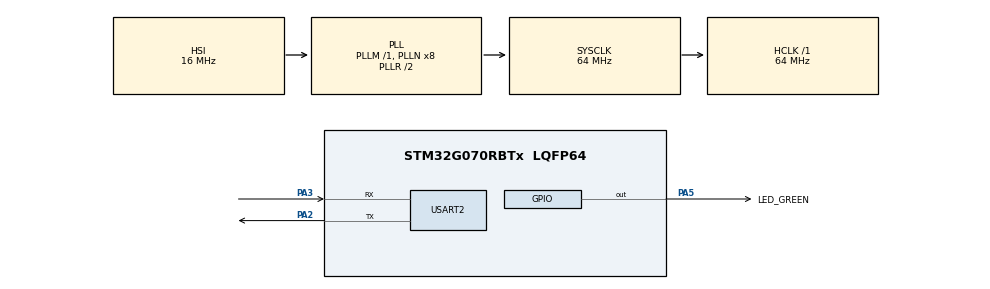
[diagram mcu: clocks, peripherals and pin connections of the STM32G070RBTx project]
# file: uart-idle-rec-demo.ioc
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Dma.Request0=USART2_RX
Dma.Request1=USART2_TX
Dma.USART2_RX.0.Direction=DMA_PERIPH_TO_MEMORY
Dma.USART2_RX.0.EventEnable=DISABLE
Dma.USART2_RX.0.Instance=DMA1_Channel1
Dma.USART2_RX.0.MemDataAlignment=DMA_MDATAALIGN_BYTE
Dma.USART2_RX.0.MemInc=DMA_MINC_ENABLE
Dma.USART2_RX.0.Mode=DMA_CIRCULAR
Dma.USART2_RX.0.PeriphDataAlignment=DMA_PDATAALIGN_BYTE
Dma.USART2_RX.0.PeriphInc=DMA_PINC_DISABLE
Dma.USART2_RX.0.Polarity=HAL_DMAMUX_REQ_GEN_RISING
Dma.USART2_RX.0.Priority=DMA_PRIORITY_LOW
Dma.USART2_RX.0.RequestNumber=1
Dma.USART2_RX.0.SignalID=NONE
Dma.USART2_RX.0.SyncEnable=DISABLE
Dma.USART2_RX.0.SyncPolarity=HAL_DMAMUX_SYNC_NO_EVENT
Dma.USART2_RX.0.SyncRequestNumber=1
Dma.USART2_RX.0.SyncSignalID=NONE
Dma.USART2_TX.1.Direction=DMA_MEMORY_TO_PERIPH
Dma.USART2_TX.1.EventEnable=DISABLE
Dma.USART2_TX.1.Instance=DMA1_Channel2
Dma.USART2_TX.1.MemDataAlignment=DMA_MDATAALIGN_BYTE
Dma.USART2_TX.1.MemInc=DMA_MINC_ENABLE
Dma.USART2_TX.1.Mode=DMA_NORMAL
Dma.USART2_TX.1.PeriphDataAlignment=DMA_PDATAALIGN_BYTE
Dma.USART2_TX.1.PeriphInc=DMA_PINC_DISABLE
Dma.USART2_TX.1.Polarity=HAL_DMAMUX_REQ_GEN_RISING
Dma.USART2_TX.1.Priority=DMA_PRIORITY_LOW
Dma.USART2_TX.1.RequestNumber=1
Dma.USART2_TX.1.SignalID=NONE
Dma.USART2_TX.1.SyncEnable=DISABLE
Dma.USART2_TX.1.SyncPolarity=HAL_DMAMUX_SYNC_NO_EVENT
Dma.USART2_TX.1.SyncRequestNumber=1
Dma.USART2_TX.1.SyncSignalID=NONE
FREERTOS.BinarySemaphores01=uart_tx_lock,Dynamic,NULL
FREERTOS.Queues01=upper_queue,16,uart_buf_t,0,Dynamic,NULL,NULL
FREERTOS.Tasks01=defaultTask,24,128,StartDefaultTask,Default,NULL,Dynamic,NULL,NULL
FREERTOS.configUSE_NEWLIB_REENTRANT=1
Mcu.Family=STM32G0
Mcu.Name=STM32G070RBTx
Mcu.Package=LQFP64
NVIC.DMA1_Channel1_IRQn=true\:3\:0\:false\:false\:true\:true\:false\:true\:true
NVIC.DMA1_Channel2_3_IRQn=true\:3\:0\:false\:false\:true\:true\:false\:true\:true
NVIC.TIM1_BRK_UP_TRG_COM_IRQn=true\:3\:0\:false\:false\:true\:false\:false\:true\:true
NVIC.TimeBase=TIM1_BRK_UP_TRG_COM_IRQn
NVIC.TimeBaseIP=TIM1
NVIC.USART2_IRQn=true\:3\:0\:false\:false\:true\:true\:true\:true\:true
PA13.GPIO_Label=TMS
PA13.Mode=Serial_Wire
PA13.Signal=SYS_SWDIO
PA14-BOOT0.GPIO_Label=TCK
PA14-BOOT0.Mode=Serial_Wire
PA14-BOOT0.Signal=SYS_SWCLK
PA2.GPIO_PuPd=GPIO_PULLUP
PA2.Mode=Asynchronous
PA2.Signal=USART2_TX
PA3.GPIO_PuPd=GPIO_PULLUP
PA3.Mode=Asynchronous
PA3.Signal=USART2_RX
PA5.GPIO_Label=LED_GREEN
PA5.GPIO_Speed=GPIO_SPEED_FREQ_HIGH
PA5.Signal=GPIO_Output
PC13.Mode=SYS_WakeUp1
PC13.Signal=SYS_WKUP2
PC14-OSC32_IN\ (PC14).Mode=LSE-External-Oscillator
PC14-OSC32_IN\ (PC14).Signal=RCC_OSC32_IN
PC15-OSC32_OUT\ (PC15).Mode=LSE-External-Oscillator
PC15-OSC32_OUT\ (PC15).Signal=RCC_OSC32_OUT
PF0-OSC_IN\ (PF0).GPIO_Label=MCO
PF0-OSC_IN\ (PF0).Mode=HSE-External-Clock-Source
PF0-OSC_IN\ (PF0).Signal=RCC_OSC_IN
ProjectManager.HeapSize=0x200
ProjectManager.StackSize=0x400
ProjectManager.TargetToolchain=STM32CubeIDE
RCC.ADCFreq_Value=64000000
RCC.AHBFreq_Value=64000000
RCC.CortexFreq_Value=64000000
RCC.EXTERNAL_CLOCK_VALUE=12288000
RCC.HCLKFreq_Value=64000000
RCC.HSE_VALUE=8000000
RCC.HSI_VALUE=16000000
RCC.SYSCLKFreq_VALUE=64000000
RCC.SYSCLKSource=RCC_SYSCLKSOURCE_PLLCLK
RCC.VCOOutputFreq_Value=128000000
USART2.VirtualMode-Asynchronous=VM_ASYNC
USART2.WordLength=WORDLENGTH_8B
VP_FREERTOS_VS_CMSIS_V2.Mode=CMSIS_V2
VP_SYS_VS_tim1.Mode=TIM1
board=NUCLEO-G070RB

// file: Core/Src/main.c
/* USER CODE BEGIN Header */
/**
  ******************************************************************************
  * @file           : main.c
  * @brief          : Main program body
  ******************************************************************************
  * @attention
  *
  * Copyright (c) 2022 STMicroelectronics.
  * All rights reserved.
  *
  * This software is licensed under terms that can be found in the LICENSE file
  * in the root directory of this software component.
  * If no LICENSE file comes with this software, it is provided AS-IS.
  *
  ******************************************************************************
  */
/* USER CODE END Header */
#include "main.h"
#include "cmsis_os.h"
#include "dma.h"
#include "usart.h"
#include "gpio.h"

/* USER CODE BEGIN Includes */
#include "string.h"
/* USER CODE END Includes */

/* USER CODE BEGIN PV */
uint8_t u2_buf[64];

volatile uint8_t u2_rx_start_pos = 0;
volatile uint8_t u2_rx_length = 0;

extern osMessageQueueId_t upper_queueHandle;
/* USER CODE END PV */

void SystemClock_Config(void);
void MX_FREERTOS_Init(void);

/* USER CODE BEGIN 0 */
void HAL_UART_ErrorCallback(UART_HandleTypeDef *huart) {
	// handle when baudrate set error
	// reset uart
//    static const char *TAG = "UART_ERR";
    uint32_t err;
    if ((err = HAL_UART_GetError(huart))) {
//        elog_w(TAG, "get a uart err :%d", err);
        if (err != HAL_UART_ERROR_NE) {
            return;
        }
        if (HAL_OK != HAL_UART_DMAStop(huart)) {
//            elog_e(TAG, "dma stop failed");
        }
        __HAL_UART_CLEAR_IDLEFLAG(huart);
        if (huart->Instance == huart2.Instance) {
            MX_USART2_UART_Init();
//            elog_w(TAG, "restart uart2");
            if (HAL_OK !=
                HAL_UARTEx_ReceiveToIdle_DMA(&huart2, (uint8_t *) &u2_buf, sizeof(u2_buf))) {
//                elog_w(TAG, "uart2 idle rec init failed");
            }
            u2_rx_start_pos = 0;
            u2_rx_length = 0;
        } else {
//            elog_w(TAG, "error uart not found");
        }
//        elog_w(TAG, "restart ok");
    } else {
//        elog_i(TAG, "no error found");
    }
}

void HAL_UARTEx_RxEventCallback(UART_HandleTypeDef *huart, uint16_t Size) {
    static uart_buf_t buf;
    if (huart->Instance == huart2.Instance) {
        u2_rx_length = Size - u2_rx_start_pos;
        if (u2_rx_length == 0) {
            return;
        }
        memcpy(buf.buf, u2_buf + u2_rx_start_pos, u2_rx_length);
        buf.len = u2_rx_length;
        osMessageQueuePut(upper_queueHandle, &buf, 0, 0);
        u2_rx_start_pos += u2_rx_length;
        if (u2_rx_start_pos >= sizeof(u2_buf)) {
            u2_rx_start_pos = 0;
        }
    }
}

void HAL_UART_TxCpltCallback(UART_HandleTypeDef *huart) {
    if (huart->Instance == huart2.Instance) {
        extern osSemaphoreId_t uart_tx_lockHandle;
        osSemaphoreRelease(uart_tx_lockHandle);
    }
}
/* USER CODE END 0 */

int main(void)
{

  /* MCU Configuration--------------------------------------------------------*/

  /* Reset of all peripherals, Initializes the Flash interface and the Systick. */
  HAL_Init();

  /* Configure the system clock */
  SystemClock_Config();

  /* Initialize all configured peripherals */
  MX_GPIO_Init();
  MX_DMA_Init();
  MX_USART2_UART_Init();
  /* USER CODE BEGIN 2 */
  if (HAL_OK !=
      HAL_UARTEx_ReceiveToIdle_DMA(&huart2, (uint8_t *) &u2_buf, sizeof(u2_buf))) {
//	  elog_w("main", "uart1 idle rec init failed");
  }
  /* USER CODE END 2 */

  /* Init scheduler */
  osKernelInitialize();  /* Call init function for freertos objects (in freertos.c) */
  MX_FREERTOS_Init();

  /* Start scheduler */
  osKernelStart();

  /* We should never get here as control is now taken by the scheduler */
  /* Infinite loop */
  while (1)
  {

  }
}

void SystemClock_Config(void)
{
  RCC_OscInitTypeDef RCC_OscInitStruct = {0};
  RCC_ClkInitTypeDef RCC_ClkInitStruct = {0};

  /** Configure the main internal regulator output voltage
  */
  HAL_PWREx_ControlVoltageScaling(PWR_REGULATOR_VOLTAGE_SCALE1);

  /** Initializes the RCC Oscillators according to the specified parameters
  * in the RCC_OscInitTypeDef structure.
  */
  RCC_OscInitStruct.OscillatorType = RCC_OSCILLATORTYPE_HSI;
  RCC_OscInitStruct.HSIState = RCC_HSI_ON;
  RCC_OscInitStruct.HSIDiv = RCC_HSI_DIV1;
  RCC_OscInitStruct.HSICalibrationValue = RCC_HSICALIBRATION_DEFAULT;
  RCC_OscInitStruct.PLL.PLLState = RCC_PLL_ON;
  RCC_OscInitStruct.PLL.PLLSource = RCC_PLLSOURCE_HSI;
  RCC_OscInitStruct.PLL.PLLM = RCC_PLLM_DIV1;
  RCC_OscInitStruct.PLL.PLLN = 8;
  RCC_OscInitStruct.PLL.PLLP = RCC_PLLP_DIV2;
  RCC_OscInitStruct.PLL.PLLR = RCC_PLLR_DIV2;
  if (HAL_RCC_OscConfig(&RCC_OscInitStruct) != HAL_OK)
  {
    Error_Handler();
  }

  /** Initializes the CPU, AHB and APB buses clocks
  */
  RCC_ClkInitStruct.ClockType = RCC_CLOCKTYPE_HCLK|RCC_CLOCKTYPE_SYSCLK
                              |RCC_CLOCKTYPE_PCLK1;
  RCC_ClkInitStruct.SYSCLKSource = RCC_SYSCLKSOURCE_PLLCLK;
  RCC_ClkInitStruct.AHBCLKDivider = RCC_SYSCLK_DIV1;
  RCC_ClkInitStruct.APB1CLKDivider = RCC_HCLK_DIV1;

  if (HAL_RCC_ClockConfig(&RCC_ClkInitStruct, FLASH_LATENCY_2) != HAL_OK)
  {
    Error_Handler();
  }
}

void HAL_TIM_PeriodElapsedCallback(TIM_HandleTypeDef *htim)
{
  if (htim->Instance == TIM1) {
    HAL_IncTick();
  }
}

void Error_Handler(void)
{
  __disable_irq();
  while (1)
  {
  }
}

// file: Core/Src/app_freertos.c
/* USER CODE BEGIN Header */
/**
  ******************************************************************************
  * File Name          : app_freertos.c
  * Description        : Code for freertos applications
  ******************************************************************************
  * @attention
  *
  * Copyright (c) 2022 STMicroelectronics.
  * All rights reserved.
  *
  * This software is licensed under terms that can be found in the LICENSE file
  * in the root directory of this software component.
  * If no LICENSE file comes with this software, it is provided AS-IS.
  *
  ******************************************************************************
  */
/* USER CODE END Header */

#include "FreeRTOS.h"
#include "task.h"
#include "main.h"
#include "cmsis_os.h"

/* USER CODE BEGIN Includes */
#include "string.h"
#include "usart.h"
/* USER CODE END Includes */

/* Definitions for defaultTask */
osThreadId_t defaultTaskHandle;
const osThreadAttr_t defaultTask_attributes = {
  .name = "defaultTask",
  .priority = (osPriority_t) osPriorityNormal,
  .stack_size = 128 * 4
};
/* Definitions for upper_queue */
osMessageQueueId_t upper_queueHandle;
const osMessageQueueAttr_t upper_queue_attributes = {
  .name = "upper_queue"
};
/* Definitions for uart_tx_lock */
osSemaphoreId_t uart_tx_lockHandle;
const osSemaphoreAttr_t uart_tx_lock_attributes = {
  .name = "uart_tx_lock"
};

void StartDefaultTask(void *argument);

void MX_FREERTOS_Init(void); /* (MISRA C 2004 rule 8.1) */

void MX_FREERTOS_Init(void) {

  /* Create the semaphores(s) */
  /* creation of uart_tx_lock */
  uart_tx_lockHandle = osSemaphoreNew(1, 1, &uart_tx_lock_attributes);

  /* Create the queue(s) */
  /* creation of upper_queue */
  upper_queueHandle = osMessageQueueNew (16, sizeof(uart_buf_t), &upper_queue_attributes);

  /* Create the thread(s) */
  /* creation of defaultTask */
  defaultTaskHandle = osThreadNew(StartDefaultTask, NULL, &defaultTask_attributes);

}

void StartDefaultTask(void *argument)
{
  /* USER CODE BEGIN StartDefaultTask */
  /* Infinite loop */
    static uart_buf_t uart_rec;
    static uint8_t state = 0;
    static uint8_t buffer[512] = "";
    static uint16_t buffer_len = 0;
    static uint8_t send_buf[512];
  for(;;)
  {
    if (osOK ==
    	osMessageQueueGet(upper_queueHandle, &uart_rec, NULL, osWaitForever)) {
    	for (uint8_t i = 0; i < uart_rec.len; i++) {
    		switch (state) {
    		case 0:
    			if (uart_rec.buf[i] == '{') {
    				state ++;
    			}
    			break;
    		case 1:
    			if (uart_rec.buf[i] == '}') {

    				osSemaphoreAcquire(uart_tx_lockHandle, osWaitForever);
    				// make sure the buffer offered to dma do not change when transmitting.
    				memcpy(send_buf, buffer, buffer_len);
    				HAL_UART_Transmit_DMA(&huart2, send_buf, buffer_len);
//    				HAL_UART_Transmit(&huart2, buffer, buffer_len, 0xff);

    				state = 0;
    				memset(buffer, 0, sizeof(buffer));
    				buffer_len = 0;
    			} else {
    				buffer[buffer_len] = uart_rec.buf[i];
    				buffer_len ++;
    				if (buffer_len >= 512) {
    					buffer_len = 0;
    					memset(buffer, 0, sizeof(buffer));
    				}
    			}
    		}
    	}
    }
  }
  /* USER CODE END StartDefaultTask */
}
